# MCXN947_cm33_core0 register map
Vendor: nxp.com; File version: 1.0
CPU: CM33 r2p0, little endian, MPU, FPU, VTOR, 3 interrupt priority bits
Registers are 32-bit, read-write, reset 0x0 unless marked. A register's access mark holds for its fields unless they carry their own. Offsets are from the block's base; [hi:lo] are bit positions; {n}, {i} and the like mark numbered series; 'fields as' and 'values as' point back to an identical list.

## CMC0 — CMC
Base 0x40048000
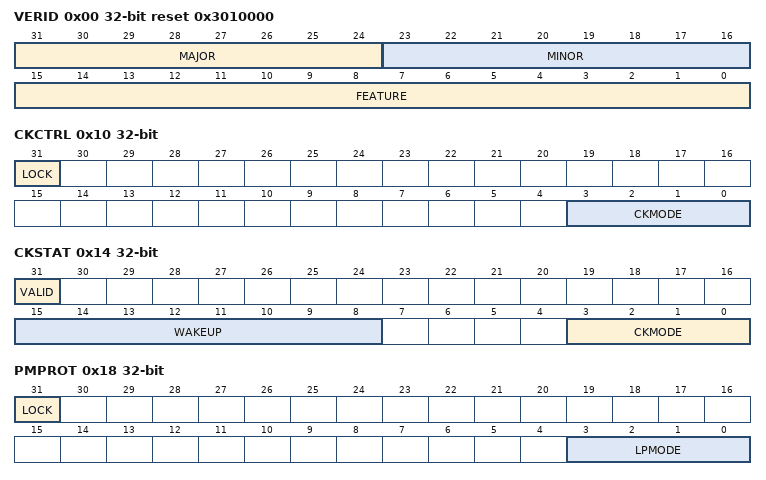
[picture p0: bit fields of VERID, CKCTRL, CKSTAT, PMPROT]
0x00 VERID ro reset 0x3010000 — Version ID
  [31:24] MAJOR — Major Version Number
  [23:16] MINOR — Minor Version Number
  [15:0] FEATURE — Feature Specification Number
0x10 CKCTRL — Clock Control
  [31] LOCK
    0=DISABLED (Allowed); 1=ENABLED (Blocked)
  [3:0] CKMODE — Clocking Mode
    0=No clock gating; 15=Core, platform, and peripheral clocks are gated, and core enters Low-Power mode
0x14 CKSTAT — Clock Status
  [31] VALID write-1-clears — Clock Status Valid
    0=DISABLED (Core clock not gated); 1=ENABLED (Core clock was gated due to Low-Power mode entry)
  [15:8] WAKEUP ro — Wake-up Source
  [3:0] CKMODE ro — Low Power Status
    0=Core clock not gated; 15=Core, platform, and peripheral clocks were gated, and power domain entered Low-Power mode
0x18 PMPROT — Power Mode Protection
  [31] LOCK
    0=DISABLED (Allowed); 1=ENABLED (Blocked)
  [3:0] LPMODE — Low-Power Mode
    0=DISABLED (Not allowed); 1=EN (Allowed); {v}=EN{v-1} (Allowed) (v=2..15)
0x1C GPMCTRL — Global Power Mode Control
  [3:0] LPMODE — Low-Power Mode
0x20 PMCTRLMAIN — Power Mode Control
  [3:0] LPMODE — Low-Power Mode
    0=Active/Sleep; 1=Deep Sleep; 3=Power Down; 15=Deep-Power Down
0x24 PMCTRLWAKE — Power Mode Control
  fields as PMCTRLMAIN
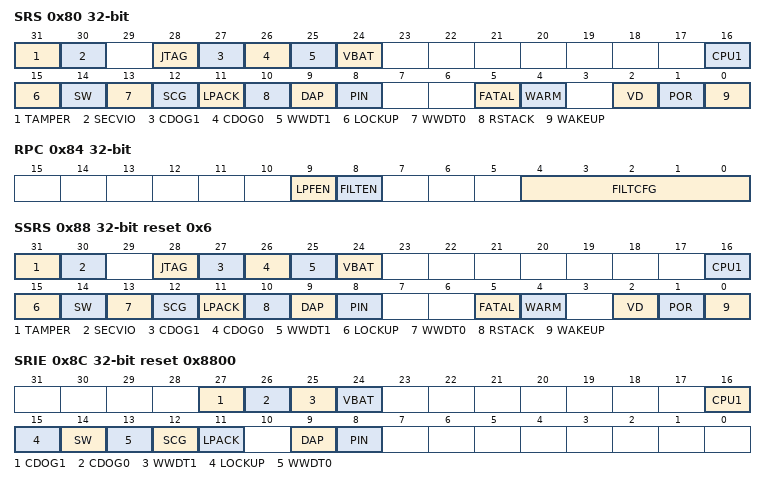
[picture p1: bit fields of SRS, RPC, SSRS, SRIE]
0x80 SRS ro reset not defined — System Reset Status
  [31] TAMPER — Tamper Reset
    0=DISABLED (Reset not generated); 1=ENABLED (Reset generated)
  [30] SECVIO — Security Violation Reset
    values as TAMPER
  [28] JTAG — JTAG System Reset
    values as TAMPER
  [27] CDOG1 — Code Watchdog 1 Reset
    0=DISABLED (Reset is not generated); 1=ENABLED (Reset is generated)
  [26] CDOG0 — Code Watchdog 0 Reset
    values as CDOG1
  [25] WWDT1 — Windowed Watchdog 1 Reset
    values as CDOG1
  [24] VBAT — VBAT System Reset
    values as TAMPER
  [16] CPU1 — CPU1 System Reset
    values as TAMPER
  [15] LOCKUP — Lockup Reset
    values as TAMPER
  [14] SW — Software Reset
    values as TAMPER
  [13] WWDT0 — Windowed Watchdog 0 Reset
    values as CDOG1
  [12] SCG — System Clock Generation Reset
    values as CDOG1
  [11] LPACK — Low Power Acknowledge Timeout Reset
    values as TAMPER
  [10] RSTACK — Reset Timeout
    values as TAMPER
  [9] DAP — Debug Access Port Reset
    0=DISABLED (Reset was not generated); 1=ENABLED (Reset was generated)
  [8] PIN — Pin Reset
    values as DAP
  [5] FATAL — Fatal Reset
    values as DAP
  [4] WARM — Warm Reset
    values as TAMPER
  [2] VD — Voltage Detect Reset
    values as TAMPER
  [1] POR — Power-on Reset
    values as TAMPER
  [0] WAKEUP — Wake-up Reset
    values as TAMPER
0x84 RPC — Reset Pin Control
  [9] LPFEN — Low-Power Filter Enable
    0=DISABLED (Disables); 1=ENABLED (Enables)
  [8] FILTEN — Filter Enable
    0=DISABLED (Disables); 1=ENABLED (Enables)
  [4:0] FILTCFG — Reset Filter Configuration
0x88 SSRS reset 0x6 — Sticky System Reset Status
  [31] TAMPER write-1-clears — Tamper Reset
    values as SRS.TAMPER
  [30] SECVIO write-1-clears — Security Violation Reset
    values as SRS.TAMPER
  [28] JTAG write-1-clears — JTAG System Reset
    values as SRS.TAMPER
  [27] CDOG1 write-1-clears — Code Watchdog 1 Reset
    values as SRS.CDOG1
  [26] CDOG0 write-1-clears — Code Watchdog 0 Reset
    values as SRS.CDOG1
  [25] WWDT1 write-1-clears — Windowed Watchdog 1 Reset
    values as SRS.CDOG1
  [24] VBAT write-1-clears — VBAT System Reset
    values as SRS.TAMPER
  [16] CPU1 write-1-clears — CPU1 Reset
    0=DISABLED (Reset not generated from CPU1 reset source.); 1=ENABLED (Reset generated from CPU1 reset source.)
  [15] LOCKUP write-1-clears — Lockup Reset
    values as SRS.TAMPER
  [14] SW write-1-clears — Software Reset
    values as SRS.TAMPER
  [13] WWDT0 write-1-clears — Windowed Watchdog 0 Reset
    values as SRS.CDOG1
  [12] SCG write-1-clears — System Clock Generation Reset
    values as SRS.CDOG1
  [11] LPACK write-1-clears — Low Power Acknowledge Timeout Reset
    values as SRS.TAMPER
  [10] RSTACK write-1-clears — Reset Timeout
    values as SRS.TAMPER
  [9] DAP write-1-clears — DAP Reset
    values as SRS.TAMPER
  [8] PIN write-1-clears — Pin Reset
    values as SRS.TAMPER
  [5] FATAL write-1-clears — Fatal Reset
    values as SRS.DAP
  [4] WARM write-1-clears — Warm Reset
    values as SRS.TAMPER
  [2] VD ro — Voltage Detect Reset
    values as SRS.TAMPER
  [1] POR write-1-clears — Power-on Reset
    values as SRS.TAMPER
  [0] WAKEUP write-1-clears — Wake-up Reset
    values as SRS.TAMPER
0x8C SRIE reset 0x8800 — System Reset Interrupt Enable
  [all] fields
    0=DISABLED (Interrupt disabled); 1=ENABLED (Interrupt enabled)
  [27] CDOG1 — Code Watchdog 1 Reset
  [26] CDOG0 — Code Watchdog 0 Reset
  [25] WWDT1 — Windowed Watchdog 1 Reset
  [24] VBAT — VBAT System Reset
  [16] CPU1 — CPU1 Reset
  [15] LOCKUP — Lockup Reset
  [14] SW — Software Reset
  [13] WWDT0 — Windowed Watchdog 0 Reset
  [12] SCG — System Clock Generation Reset
  [11] LPACK — Low Power Acknowledge Timeout Reset
  [9] DAP — DAP Reset
  [8] PIN — Pin Reset
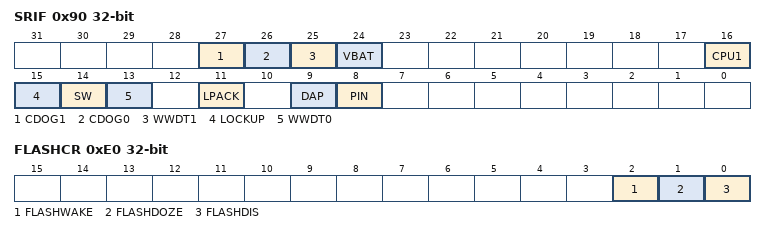
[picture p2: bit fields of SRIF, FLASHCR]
0x90 SRIF write-1-clears — System Reset Interrupt Flag
  [all] fields
    0=DISABLED (Reset source not pending); 1=ENABLED (Reset source pending)
  [27] CDOG1 write-1-clears — Code Watchdog 1 Reset
  [26] CDOG0 write-1-clears — Code Watchdog 0 Reset
  [25] WWDT1 write-1-clears — Windowed Watchdog 1 Reset
  [24] VBAT write-1-clears — VBAT System Reset
  [16] CPU1 write-1-clears — CPU1 Reset
  [15] LOCKUP write-1-clears — Lockup Reset
  [14] SW write-1-clears — Software Reset
  [13] WWDT0 write-1-clears — Windowed Watchdog 0 Reset
  [11] LPACK write-1-clears — Low Power Acknowledge Timeout Reset
  [9] DAP write-1-clears — DAP Reset
  [8] PIN write-1-clears — Pin Reset
0x9C RSTCNT ro — Reset Count Register
  [7:0] COUNT
0xA0 MR0 write-1-clears — Mode
  [0] ISPMODE_n write-1-clears — In System Programming Mode
0xB0 FM0 — Force Mode
  [0] FORCECFG — Boot Configuration
    0=DISABLED (No effect); 1=ENABLED (Asserts)
0xC0 SRAMDIS0 — SRAM Disable
  [31:0] DIS
0xD0 SRAMRET0 — SRAM Retention
  [31:0] RET
0xE0 FLASHCR — Flash Control
  [2] FLASHWAKE
    0=DISABLED (No effect); 1=ENABLED (Flash memory is not disabled during flash memory accesses)
  [1] FLASHDOZE
    0=DISABLED (No effect); 1=ENABLED (Flash memory is disabled when core is sleeping (CKMODE > 0))
  [0] FLASHDIS — Flash Disable
    0=DISABLED (No effect); 1=ENABLED (Flash memory is disabled)
0x100 BSR — BootROM Status
  [31:0] STAT — Provides status information written by the BootROM.
0x10C BLR reset 0x2 — BootROM Lock Register
  [2:0] LOCK
    2=BootROM Status and Lock Registers can be written; 5=BootROM Status and Lock Registers cannot be written
0x110 CORECTL — Core Control
  [0] NPIE — Non-maskable Pin Interrupt Enable
    0=DISABLED (Disables); 1=ENABLED (Enables)
0x120 DBGCTL — Debug Control
  [0] SOD — Sleep Or Debug
    0=DISABLED (Remains enabled); 1=ENABLED (Disabled)
